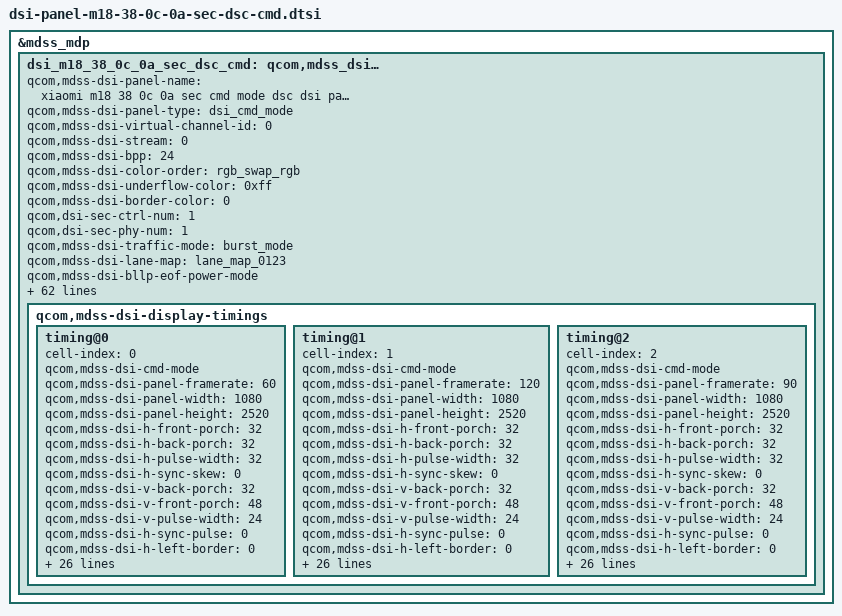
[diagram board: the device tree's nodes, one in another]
&mdss_mdp {
	dsi_m18_38_0c_0a_sec_dsc_cmd: qcom,mdss_dsi_m18_38_0c_0a_sec_dsc_cmd {
		qcom,mdss-dsi-panel-name = "xiaomi m18 38 0c 0a sec cmd mode dsc dsi panel";
		qcom,mdss-dsi-panel-type = "dsi_cmd_mode";
		qcom,mdss-dsi-virtual-channel-id = <0>;
		qcom,mdss-dsi-stream = <0>;
		qcom,mdss-dsi-bpp = <24>;
		qcom,mdss-dsi-color-order = "rgb_swap_rgb";
		qcom,mdss-dsi-underflow-color = <0xff>;
		qcom,mdss-dsi-border-color = <0>;
		qcom,dsi-sec-ctrl-num = <1>;
		qcom,dsi-sec-phy-num = <1>;

		qcom,mdss-dsi-traffic-mode = "burst_mode";
		qcom,mdss-dsi-lane-map = "lane_map_0123";
		qcom,mdss-dsi-bllp-eof-power-mode;
		qcom,mdss-dsi-bllp-power-mode;
		qcom,mdss-dsi-lane-0-state;
		qcom,mdss-dsi-lane-1-state;
		qcom,mdss-dsi-lane-2-state;
		qcom,mdss-dsi-lane-3-state;
		qcom,mdss-dsi-dma-trigger = "trigger_sw";
		qcom,mdss-dsi-mdp-trigger = "none";
		qcom,mdss-dsi-reset-sequence = <0 5>, <1 10>;
		qcom,mdss-pan-physical-width-dimension = <657>;
		qcom,mdss-pan-physical-height-dimension = <1532>;
		qcom,mdss-dsi-te-pin-select = <1>;
		qcom,mdss-dsi-wr-mem-start = <0x2c>;
		qcom,mdss-dsi-wr-mem-continue = <0x3c>;
		qcom,mdss-dsi-te-dcs-command = <1>;
		qcom,mdss-dsi-te-check-enable;
		qcom,mdss-dsi-te-using-te-pin;
		qcom,mdss-dsi-tx-eot-append;
		qcom,mdss-dsi-lp11-init;

		qcom,mdss-dsi-bl-inverted-dbv;
		qcom,bl-update-flag = "delay_until_first_frame";

		qcom,mdss-dsi-dma-schedule-line = <1>;
		qcom,mdss-dsi-dma-schedule-window = <50>;

		qcom,mdss-dsi-panel-hdr-enabled;
		qcom,mdss-dsi-panel-hdr-color-primaries = <14500 15500 32000
			17000 15500 30000 8000 3000>;
		qcom,mdss-dsi-panel-peak-brightness = <10000000>;
		qcom,mdss-dsi-panel-blackness-level = <3230>;

		qcom,mdss-dsi-display-timings {
			timing@0{ /* 60Hz */
				#include "dsi-panel-m18-38-0c-0a-sec-dsc-cmd-common.dtsi"
				cell-index = <0>;
				qcom,mdss-dsi-cmd-mode;
				qcom,mdss-dsi-panel-framerate = <60>;
				qcom,mdss-dsi-panel-width = <1080>;
				qcom,mdss-dsi-panel-height = <2520>;
				qcom,mdss-dsi-h-front-porch = <32>;
				qcom,mdss-dsi-h-back-porch = <32>;
				qcom,mdss-dsi-h-pulse-width = <32>;
				qcom,mdss-dsi-h-sync-skew = <0>;
				qcom,mdss-dsi-v-back-porch = <32>;
				qcom,mdss-dsi-v-front-porch = <48>;
				qcom,mdss-dsi-v-pulse-width = <24>;
				qcom,mdss-dsi-h-sync-pulse = <0>;
				qcom,mdss-dsi-h-left-border = <0>;
				qcom,mdss-dsi-h-right-border = <0>;
				qcom,mdss-dsi-v-top-border = <0>;
				qcom,mdss-dsi-v-bottom-border = <0>;
				qcom,mdss-dsi-panel-clockrate = <965000000>;
				qcom,mdss-dsi-panel-jitter = <0x5 0x1>;
				qcom,mdss-mdp-transfer-time-us = <7300>;

				qcom,mdss-dsi-on-command = [
					#include "dsi-panel-m18-38-0c-0a-sec-dsc-cmd-dsi-on-common.dtsi"
					/* Frequency Select 60.07Hz */
					39 00 00 40 00 00 03 F0 5A 5A
					39 00 00 40 00 00 02 60 08
					39 00 00 40 00 00 04 B0 00 16 F2
					39 00 00 40 00 00 03 F2 01 61
					39 00 00 40 00 00 04 B0 01 D4 CB
					39 00 00 40 00 00 02 CB 1A
					39 00 00 40 00 00 04 B0 01 DA CB
					39 00 00 40 00 00 02 CB 1A
					39 00 00 40 00 00 02 F7 0F
					39 00 00 00 00 00 03 F0 A5 A5
					/* Display On */
					05 00 00 00 00 00 02 29 00
				];
				qcom,mdss-dsi-on-command-state = "dsi_lp_mode";

				qcom,mdss-dsi-off-command = [
					05 00 00 00 00 00 02 28 00
					05 00 00 00 78 00 02 10 00
				];
				qcom,mdss-dsi-off-command-state = "dsi_lp_mode";

				qcom,mdss-dsi-timing-switch-command = [
					/* Frequency Select 60.07Hz */
					39 00 00 40 00 00 03 F0 5A 5A
					39 00 00 40 00 00 02 60 08
					39 00 00 40 00 00 04 B0 00 16 F2
					39 00 00 40 00 00 03 F2 01 61
					39 00 00 40 00 00 04 B0 01 D4 CB
					39 00 00 40 00 00 02 CB 1A
					39 00 00 40 00 00 04 B0 01 DA CB
					39 00 00 40 00 00 02 CB 1A
					39 00 00 40 00 00 02 F7 0F
					39 00 00 00 00 00 03 F0 A5 A5
				];
				qcom,mdss-dsi-timing-switch-command-state = "dsi_hs_mode";

				qcom,mdss-dsi-nolp-command = [
					39 00 00 40 00 00 03 F0 5A 5A
					39 00 00 40 00 00 02 60 08
					39 00 00 40 00 00 02 53 20
					39 00 00 40 00 00 03 51 00 00
					39 00 00 40 00 00 02 F7 0F
					39 00 00 00 00 00 03 F0 A5 A5
				];
				qcom,mdss-dsi-nolp-command-state = "dsi_lp_mode";

				qcom,compression-mode = "dsc";
				qcom,mdss-dsc-slice-height = <40>;
				qcom,mdss-dsc-slice-width = <540>;
				qcom,mdss-dsc-slice-per-pkt = <2>;
				qcom,mdss-dsc-bit-per-component = <8>;
				qcom,mdss-dsc-bit-per-pixel = <8>;
				qcom,mdss-dsc-block-prediction-enable;
			};

			timing@1{ /* 120Hz */
				#include "dsi-panel-m18-38-0c-0a-sec-dsc-cmd-common.dtsi"
				cell-index = <1>;
				qcom,mdss-dsi-cmd-mode;
				qcom,mdss-dsi-panel-framerate = <120>;
				qcom,mdss-dsi-panel-width = <1080>;
				qcom,mdss-dsi-panel-height = <2520>;
				qcom,mdss-dsi-h-front-porch = <32>;
				qcom,mdss-dsi-h-back-porch = <32>;
				qcom,mdss-dsi-h-pulse-width = <32>;
				qcom,mdss-dsi-h-sync-skew = <0>;
				qcom,mdss-dsi-v-back-porch = <32>;
				qcom,mdss-dsi-v-front-porch = <48>;
				qcom,mdss-dsi-v-pulse-width = <24>;
				qcom,mdss-dsi-h-sync-pulse = <0>;
				qcom,mdss-dsi-h-left-border = <0>;
				qcom,mdss-dsi-h-right-border = <0>;
				qcom,mdss-dsi-v-top-border = <0>;
				qcom,mdss-dsi-v-bottom-border = <0>;
				qcom,mdss-dsi-panel-clockrate = <965000000>;
				qcom,mdss-dsi-panel-jitter = <0x5 0x1>;
				qcom,mdss-mdp-transfer-time-us = <7300>;

				qcom,mdss-dsi-on-command = [
					#include "dsi-panel-m18-38-0c-0a-sec-dsc-cmd-dsi-on-common.dtsi"
					/* Frequency Select 120.14Hz */
					39 00 00 40 00 00 03 F0 5A 5A
					39 00 00 40 00 00 02 60 00
					39 00 00 40 00 00 04 B0 00 16 F2
					39 00 00 40 00 00 03 F2 01 61
					39 00 00 40 00 00 04 B0 01 D4 CB
					39 00 00 40 00 00 02 CB 1A
					39 00 00 40 00 00 04 B0 01 DA CB
					39 00 00 40 00 00 02 CB 1A
					39 00 00 40 00 00 02 F7 0F
					39 00 00 00 00 00 03 F0 A5 A5
					/* Display On */
					05 00 00 00 00 00 02 29 00
				];
				qcom,mdss-dsi-on-command-state = "dsi_lp_mode";

				qcom,mdss-dsi-off-command = [
					05 00 00 00 00 00 02 28 00
					05 00 00 00 78 00 02 10 00
				];
				qcom,mdss-dsi-off-command-state = "dsi_lp_mode";

				qcom,mdss-dsi-timing-switch-command = [
					/* Frequency Select 120.14Hz */
					39 00 00 40 00 00 03 F0 5A 5A
					39 00 00 40 00 00 02 60 00
					39 00 00 40 00 00 04 B0 00 16 F2
					39 00 00 40 00 00 03 F2 01 61
					39 00 00 40 00 00 04 B0 01 D4 CB
					39 00 00 40 00 00 02 CB 1A
					39 00 00 40 00 00 04 B0 01 DA CB
					39 00 00 40 00 00 02 CB 1A
					39 00 00 40 00 00 02 F7 0F
					39 00 00 00 00 00 03 F0 A5 A5
				];
				qcom,mdss-dsi-timing-switch-command-state = "dsi_hs_mode";

				qcom,mdss-dsi-nolp-command = [
					39 00 00 40 00 00 03 F0 5A 5A
					39 00 00 40 00 00 02 60 00
					39 00 00 40 00 00 02 53 20
					39 00 00 40 00 00 03 51 00 00
					39 00 00 40 00 00 02 F7 0F
					39 00 00 00 00 00 03 F0 A5 A5
				];
				qcom,mdss-dsi-nolp-command-state = "dsi_lp_mode";

				qcom,compression-mode = "dsc";
				qcom,mdss-dsc-slice-height = <40>;
				qcom,mdss-dsc-slice-width = <540>;
				qcom,mdss-dsc-slice-per-pkt = <2>;
				qcom,mdss-dsc-bit-per-component = <8>;
				qcom,mdss-dsc-bit-per-pixel = <8>;
				qcom,mdss-dsc-block-prediction-enable;
			};

			timing@2{ /* 90Hz */
				#include "dsi-panel-m18-38-0c-0a-sec-dsc-cmd-common.dtsi"
				cell-index = <2>;
				qcom,mdss-dsi-cmd-mode;
				qcom,mdss-dsi-panel-framerate = <90>;
				qcom,mdss-dsi-panel-width = <1080>;
				qcom,mdss-dsi-panel-height = <2520>;
				qcom,mdss-dsi-h-front-porch = <32>;
				qcom,mdss-dsi-h-back-porch = <32>;
				qcom,mdss-dsi-h-pulse-width = <32>;
				qcom,mdss-dsi-h-sync-skew = <0>;
				qcom,mdss-dsi-v-back-porch = <32>;
				qcom,mdss-dsi-v-front-porch = <48>;
				qcom,mdss-dsi-v-pulse-width = <24>;
				qcom,mdss-dsi-h-sync-pulse = <0>;
				qcom,mdss-dsi-h-left-border = <0>;
				qcom,mdss-dsi-h-right-border = <0>;
				qcom,mdss-dsi-v-top-border = <0>;
				qcom,mdss-dsi-v-bottom-border = <0>;
				qcom,mdss-dsi-panel-clockrate = <965000000>;
				qcom,mdss-dsi-panel-jitter = <0x5 0x1>;
				qcom,mdss-mdp-transfer-time-us = <7300>;

				qcom,mdss-dsi-on-command = [
					#include "dsi-panel-m18-38-0c-0a-sec-dsc-cmd-dsi-on-common.dtsi"
					/* Frequency Select 90Hz */
					39 00 00 40 00 00 03 F0 5A 5A
					39 00 00 40 00 00 02 60 00
					39 00 00 40 00 00 04 B0 00 16 F2
					39 00 00 40 00 00 03 F2 01 D6
					39 00 00 40 00 00 04 B0 01 D4 CB
					39 00 00 40 00 00 02 CB 37
					39 00 00 40 00 00 04 B0 01 DA CB
					39 00 00 40 00 00 02 CB 37
					39 00 00 40 00 00 02 F7 0F
					39 00 00 00 00 00 03 F0 A5 A5
					/* Display On */
					05 00 00 00 00 00 02 29 00];
				qcom,mdss-dsi-on-command-state = "dsi_lp_mode";

				qcom,mdss-dsi-off-command = [
					05 00 00 00 00 00 02 28 00
					05 00 00 00 78 00 02 10 00];
				qcom,mdss-dsi-off-command-state = "dsi_lp_mode";

				qcom,mdss-dsi-timing-switch-command = [
					39 00 00 40 00 00 03 F0 5A 5A
					39 00 00 40 00 00 02 60 00
					39 00 00 40 00 00 04 B0 00 16 F2
					39 00 00 40 00 00 03 F2 01 D6
					39 00 00 40 00 00 04 B0 01 D4 CB
					39 00 00 40 00 00 02 CB 37
					39 00 00 40 00 00 04 B0 01 DA CB
					39 00 00 40 00 00 02 CB 37
					39 00 00 40 00 00 02 F7 0F
					39 00 00 00 00 00 03 F0 A5 A5
				];
				qcom,mdss-dsi-timing-switch-command-state = "dsi_hs_mode";

				qcom,mdss-dsi-nolp-command = [
					39 00 00 40 00 00 03 F0 5A 5A
					39 00 00 40 00 00 02 60 00
					39 00 00 40 00 00 04 B0 00 16 F2
					39 00 00 40 00 00 03 F2 01 D6
					39 00 00 40 00 00 04 B0 01 D4 CB
					39 00 00 40 00 00 02 CB 37
					39 00 00 40 00 00 04 B0 01 DA CB
					39 00 00 40 00 00 02 CB 37
					39 00 00 40 00 00 02 53 20
					39 00 00 40 00 00 02 F7 0F
					39 00 00 00 00 00 03 F0 A5 A5
				];
				qcom,mdss-dsi-nolp-command-state = "dsi_lp_mode";

				qcom,compression-mode = "dsc";
				qcom,mdss-dsc-slice-height = <40>;
				qcom,mdss-dsc-slice-width = <540>;
				qcom,mdss-dsc-slice-per-pkt = <2>;
				qcom,mdss-dsc-bit-per-component = <8>;
				qcom,mdss-dsc-bit-per-pixel = <8>;
				qcom,mdss-dsc-block-prediction-enable;
			};
		};
	};
};

&dsi_m18_38_0c_0a_sec_dsc_cmd {
	/* IRQF_ONESHOT | IRQF_TRIGGER_HIGH */
	mi,esd-err-irq-gpio = <&tlmm 174 0x2004>;
	mi,panel-id = <0x004D3138 0x53380C00>;

	mi,mdss-dsi-panel-wp-read-command = [06 01 00 01 00 00 01 A1];
	mi,mdss-dsi-panel-wp-read-command-state = "dsi_lp_mode";
	mi,mdss-dsi-panel-wp-read-length = <4>;

	mi,panel-on-dimming-delay = <120>;
	mi,doze-hbm-dbv-level = <243>;
	mi,doze-lbm-dbv-level = <21>;
	mi,max-brightness-clone = <16383>;
	mi,mdss-dsi-fac-bl-max-level = <2047>;
	mi,mdss-fac-brightness-max-level = <2047>;
	mi,mdss-dsi-panel-dc-threshold = <375>;
	mi,dc-feature-enabled;
	mi,thermal-dimming-flag;
	mi,dc-feature-type = "crc_skip_backlight";
	mi,normal-to-aod-doze-51reg-update-value = <2453>;

	mi,flatmode-status-check-enabled;
	mi,mdss-dsi-panel-flatmode-status-offset-command = [
		39 00 00 40 00 00 03 F0 5A 5A
		39 00 00 00 00 00 04 B0 02 79 92
	];
	mi,mdss-dsi-panel-flatmode-status-offset-command-state = "dsi_lp_mode";

	mi,mdss-dsi-panel-flatmode-status-command = [
		06 01 00 01 00 00 01 92
	];
	mi,mdss-dsi-panel-flatmode-status-command-state = "dsi_lp_mode";

	mi,mdss-dsi-panel-flatmode-status-offset-end-command = [
		39 00 00 00 00 00 03 F0 A5 A5
	];
	mi,mdss-dsi-panel-flatmode-status-offset-end-command-state = "dsi_lp_mode";

	mi,mdss-dsi-panel-flatmode-status-read-length = <1>;
	mi,mdss-dsi-panel-flatmode-on-status-value = <0x25>;
};
